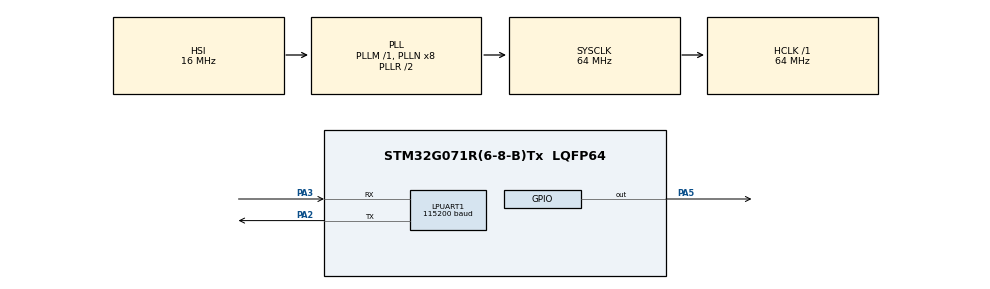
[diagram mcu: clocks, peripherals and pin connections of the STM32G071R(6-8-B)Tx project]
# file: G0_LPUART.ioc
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LPUART1.BaudRate=115200
LPUART1.WordLength=UART_WORDLENGTH_8B
Mcu.Family=STM32G0
Mcu.Name=STM32G071R(6-8-B)Tx
Mcu.Package=LQFP64
PA2.Mode=Asynchronous
PA2.Signal=LPUART1_TX
PA3.Mode=Asynchronous
PA3.Signal=LPUART1_RX
PA5.Signal=GPIO_Output
ProjectManager.HeapSize=0x200
ProjectManager.StackSize=0x400
ProjectManager.TargetToolchain=MDK-ARM V5
RCC.ADCFreq_Value=64000000
RCC.AHBFreq_Value=64000000
RCC.CortexFreq_Value=64000000
RCC.EXTERNAL_CLOCK_VALUE=48000
RCC.HCLKFreq_Value=64000000
RCC.HSE_VALUE=8000000
RCC.HSI_VALUE=16000000
RCC.LSE_VALUE=32768
RCC.SYSCLKFreq_VALUE=64000000
RCC.SYSCLKSource=RCC_SYSCLKSOURCE_PLLCLK
RCC.VCOOutputFreq_Value=128000000
board=custom

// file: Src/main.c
/* USER CODE BEGIN Header */
/**
  ******************************************************************************
  * @file           : main.c
  * @brief          : Main program body
  ******************************************************************************
  ** This notice applies to any and all portions of this file
  * that are not between comment pairs USER CODE BEGIN and
  * USER CODE END. Other portions of this file, whether
  * inserted by the user or by software development tools
  * are owned by their respective copyright owners.
  *
  * COPYRIGHT(c) 2019 STMicroelectronics
  *
  * Redistribution and use in source and binary forms, with or without modification,
  * are permitted provided that the following conditions are met:
  *   1. Redistributions of source code must retain the above copyright notice,
  *      this list of conditions and the following disclaimer.
  *   2. Redistributions in binary form must reproduce the above copyright notice,
  *      this list of conditions and the following disclaimer in the documentation
  *      and/or other materials provided with the distribution.
  *   3. Neither the name of STMicroelectronics nor the names of its contributors
  *      may be used to endorse or promote products derived from this software
  *      without specific prior written permission.
  *
  * THIS SOFTWARE IS PROVIDED BY THE COPYRIGHT HOLDERS AND CONTRIBUTORS "AS IS"
  * AND ANY EXPRESS OR IMPLIED WARRANTIES, INCLUDING, BUT NOT LIMITED TO, THE
  * IMPLIED WARRANTIES OF MERCHANTABILITY AND FITNESS FOR A PARTICULAR PURPOSE ARE
  * DISCLAIMED. IN NO EVENT SHALL THE COPYRIGHT HOLDER OR CONTRIBUTORS BE LIABLE
  * FOR ANY DIRECT, INDIRECT, INCIDENTAL, SPECIAL, EXEMPLARY, OR CONSEQUENTIAL
  * DAMAGES (INCLUDING, BUT NOT LIMITED TO, PROCUREMENT OF SUBSTITUTE GOODS OR
  * SERVICES; LOSS OF USE, DATA, OR PROFITS; OR BUSINESS INTERRUPTION) HOWEVER
  * CAUSED AND ON ANY THEORY OF LIABILITY, WHETHER IN CONTRACT, STRICT LIABILITY,
  * OR TORT (INCLUDING NEGLIGENCE OR OTHERWISE) ARISING IN ANY WAY OUT OF THE USE
  * OF THIS SOFTWARE, EVEN IF ADVISED OF THE POSSIBILITY OF SUCH DAMAGE.
  *
  ******************************************************************************
  */
/* USER CODE END Header */

#include "main.h"

/* USER CODE BEGIN Includes */
#include <stdio.h>
#include "string.h"
/* USER CODE END Includes */

/* USER CODE BEGIN PM */
	void translator();
/* USER CODE END PM */

UART_HandleTypeDef hlpuart1;

/* USER CODE BEGIN PV */
char letter[] =
        {'a', 'b', 'c', 'd', 'e', 'f', 'g', 'h', 'i', 'j', 'k', 'l',
         'm', 'n', 'o', 'p', 'q', 'r', 's', 't', 'u', 'v', 'w', 'x',
         'y', 'z',  '1', '2', '3', '4', '5', '6', '7', '8', '9', '0',
         ',', '.', '?', ' '};

char* morse[] =
        {".-", "-...", "-.-.", "-..", ".", "..-.", "--.", "....", "..",
         ".---", "-.-", ".-..", "--", "-.", "---", ".---.", "--.-", ".-.",
         "...", "-", "..-", "...-", ".--", "-..-", "-.--", "--..", ".----",
         "..---", "...--", "....-", ".....", "-....", "--...", "---..", "----.",
         "-----", "--..--", ".-.-.-", "..--..", ""};
/* USER CODE END PV */

void SystemClock_Config(void);
static void MX_GPIO_Init(void);
static void MX_LPUART1_UART_Init(void);
/* USER CODE BEGIN PFP */
#define PUTCHAR_PROTOTYPE int fputc(int ch, FILE *f)
#define  GETCHAR_PROTOTYPE  int f getc ( FILE * f)
/* USER CODE END PFP */

/* USER CODE BEGIN 0 */
void translator(){   //debugging
    char input[50] = {"Hello world"};
    //fgets(input, 2048 ,stdin);
    //printf("%s", input);
    //convert = (char*)malloc(strlen(convert)*sizeof(char));
		HAL_Delay(2000);

    //String convert = Serial.readStringUntil("\n'); //reads serial data line until new line
    //Serial.println(convert);
    printf("Input is: %s\r\n", input);
    int inputlength = strlen(input);
    int letterlength = strlen(letter);
    char buffer[ 50 ];    //buffer for holding converted strings

    for (int i = 0; i<inputlength; i++){
        for(int j = 0; j<letterlength; j++){
            if(input[i] == letter[j]){
                strcat( buffer, morse[j]);  //adds the morse code to the buffer
                strcat( buffer, " ");
            }
        }
    }
    printf("The morse code output is: %s\r\n", buffer);

//  int length = input.length();    //Get the length of the string
    //Serial.println(convert);    //Print received text for debugging purposes
    printf("The binary output: ");
    for(int i = 0; i<inputlength; i++){  //We cylce through each character so we can convert it to binary individually
        char inputChar = input[i];

        // This will 'output' the binary representation of 'inputChar' as 8 characters of '1's and '0's, MSB first.
        for ( uint8_t bitMask = 128; bitMask != 0; bitMask = bitMask >> 1 ) {   //cycle through bit mask
            if ( inputChar & bitMask ) {
                printf("%d", 1);
            } else {                //End up with either a one or a zero
                printf("%d", 0);
            }
        }
    }
    printf("\n");

}
/* USER CODE END 0 */

int main(void)
{

  /* MCU Configuration--------------------------------------------------------*/

  /* Reset of all peripherals, Initializes the Flash interface and the Systick. */
  HAL_Init();

  /* Configure the system clock */
  SystemClock_Config();

  /* Initialize all configured peripherals */
  MX_GPIO_Init();
  MX_LPUART1_UART_Init();

  /* Infinite loop */
  /* USER CODE BEGIN WHILE */
  while (1)
  {
		//printf("** Hello World ** \n\r");
		HAL_GPIO_TogglePin(GPIOA, GPIO_PIN_5);
		printf("--> SMT32 ESSENTIALS Printf to (LP)UART ++ \r\n");
		translator();
		HAL_Delay(5000);
    /* USER CODE END WHILE */

  }
}

void SystemClock_Config(void)
{
  RCC_OscInitTypeDef RCC_OscInitStruct = {0};
  RCC_ClkInitTypeDef RCC_ClkInitStruct = {0};
  RCC_PeriphCLKInitTypeDef PeriphClkInit = {0};

  /**Configure the main internal regulator output voltage
  */
  HAL_PWREx_ControlVoltageScaling(PWR_REGULATOR_VOLTAGE_SCALE1);
  /**Initializes the CPU, AHB and APB busses clocks
  */
  RCC_OscInitStruct.OscillatorType = RCC_OSCILLATORTYPE_HSI;
  RCC_OscInitStruct.HSIState = RCC_HSI_ON;
  RCC_OscInitStruct.HSIDiv = RCC_HSI_DIV1;
  RCC_OscInitStruct.HSICalibrationValue = RCC_HSICALIBRATION_DEFAULT;
  RCC_OscInitStruct.PLL.PLLState = RCC_PLL_ON;
  RCC_OscInitStruct.PLL.PLLSource = RCC_PLLSOURCE_HSI;
  RCC_OscInitStruct.PLL.PLLM = RCC_PLLM_DIV1;
  RCC_OscInitStruct.PLL.PLLN = 8;
  RCC_OscInitStruct.PLL.PLLP = RCC_PLLP_DIV2;
  RCC_OscInitStruct.PLL.PLLQ = RCC_PLLQ_DIV2;
  RCC_OscInitStruct.PLL.PLLR = RCC_PLLR_DIV2;
  if (HAL_RCC_OscConfig(&RCC_OscInitStruct) != HAL_OK)
  {
    Error_Handler();
  }
  /**Initializes the CPU, AHB and APB busses clocks
  */
  RCC_ClkInitStruct.ClockType = RCC_CLOCKTYPE_HCLK|RCC_CLOCKTYPE_SYSCLK
                              |RCC_CLOCKTYPE_PCLK1;
  RCC_ClkInitStruct.SYSCLKSource = RCC_SYSCLKSOURCE_PLLCLK;
  RCC_ClkInitStruct.AHBCLKDivider = RCC_SYSCLK_DIV1;
  RCC_ClkInitStruct.APB1CLKDivider = RCC_HCLK_DIV1;

  if (HAL_RCC_ClockConfig(&RCC_ClkInitStruct, FLASH_LATENCY_2) != HAL_OK)
  {
    Error_Handler();
  }
  /**Initializes the peripherals clocks
  */
  PeriphClkInit.PeriphClockSelection = RCC_PERIPHCLK_LPUART1;
  PeriphClkInit.Lpuart1ClockSelection = RCC_LPUART1CLKSOURCE_PCLK1;
  if (HAL_RCCEx_PeriphCLKConfig(&PeriphClkInit) != HAL_OK)
  {
    Error_Handler();
  }
}

static void MX_LPUART1_UART_Init(void)
{

  hlpuart1.Instance = LPUART1;
  hlpuart1.Init.BaudRate = 115200;
  hlpuart1.Init.WordLength = UART_WORDLENGTH_8B;
  hlpuart1.Init.StopBits = UART_STOPBITS_1;
  hlpuart1.Init.Parity = UART_PARITY_NONE;
  hlpuart1.Init.Mode = UART_MODE_TX_RX;
  hlpuart1.Init.HwFlowCtl = UART_HWCONTROL_NONE;
  hlpuart1.Init.OneBitSampling = UART_ONE_BIT_SAMPLE_DISABLE;
  hlpuart1.Init.ClockPrescaler = UART_PRESCALER_DIV1;
  hlpuart1.AdvancedInit.AdvFeatureInit = UART_ADVFEATURE_NO_INIT;
  hlpuart1.FifoMode = UART_FIFOMODE_DISABLE;
  if (HAL_UART_Init(&hlpuart1) != HAL_OK)
  {
    Error_Handler();
  }
  if (HAL_UARTEx_SetTxFifoThreshold(&hlpuart1, UART_TXFIFO_THRESHOLD_1_8) != HAL_OK)
  {
    Error_Handler();
  }
  if (HAL_UARTEx_SetRxFifoThreshold(&hlpuart1, UART_RXFIFO_THRESHOLD_1_8) != HAL_OK)
  {
    Error_Handler();
  }
  if (HAL_UARTEx_DisableFifoMode(&hlpuart1) != HAL_OK)
  {
    Error_Handler();
  }

}

static void MX_GPIO_Init(void)
{
  GPIO_InitTypeDef GPIO_InitStruct = {0};

  /* GPIO Ports Clock Enable */
  __HAL_RCC_GPIOA_CLK_ENABLE();

  /*Configure GPIO pin Output Level */
  HAL_GPIO_WritePin(GPIOA, GPIO_PIN_5, GPIO_PIN_RESET);

  /*Configure GPIO pin : PA5 */
  GPIO_InitStruct.Pin = GPIO_PIN_5;
  GPIO_InitStruct.Mode = GPIO_MODE_OUTPUT_PP;
  GPIO_InitStruct.Pull = GPIO_NOPULL;
  GPIO_InitStruct.Speed = GPIO_SPEED_FREQ_LOW;
  HAL_GPIO_Init(GPIOA, &GPIO_InitStruct);

}

/* USER CODE BEGIN 4 */
PUTCHAR_PROTOTYPE
{
HAL_UART_Transmit(&hlpuart1, (uint8_t *)&ch, 1, 0xFFFF);
return ch;
}

/* USER CODE END 4 */

void Error_Handler(void)
{
}

/************************ (C) COPYRIGHT STMicroelectronics *****END OF FILE****/
